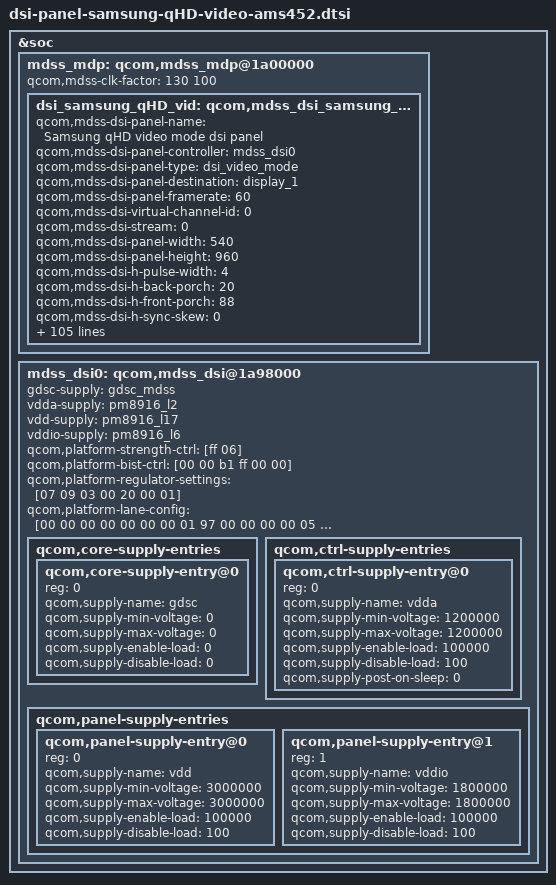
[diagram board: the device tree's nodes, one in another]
/* Copyright (c) 2013-2014, The Linux Foundation. All rights reserved.
 *
 * This program is free software; you can redistribute it and/or modify
 * it under the terms of the GNU General Public License version 2 and
 * only version 2 as published by the Free Software Foundation.
 *
 * This program is distributed in the hope that it will be useful,
 * but WITHOUT ANY WARRANTY; without even the implied warranty of
 * MERCHANTABILITY or FITNESS FOR A PARTICULAR PURPOSE.  See the
 * GNU General Public License for more details.
 */

/*---------------------------------------------------------------------------
 * This file is autogenerated file using gcdb parser. Please do not edit it.
 * Update input XML file to add a new entry or update variable in this file
 * VERSION = "1.0"
 *---------------------------------------------------------------------------

 */
&mdss_mdp {
	dsi_samsung_qHD_vid: qcom,mdss_dsi_samsung_qHD_video {
		qcom,mdss-dsi-panel-name = "Samsung qHD video mode dsi panel";
		qcom,mdss-dsi-panel-controller = <&mdss_dsi0>;
		qcom,mdss-dsi-panel-type = "dsi_video_mode";
		qcom,mdss-dsi-panel-destination = "display_1";
		qcom,mdss-dsi-panel-framerate = <60>;
		qcom,mdss-dsi-virtual-channel-id = <0>;
		qcom,mdss-dsi-stream = <0>;
		qcom,mdss-dsi-panel-width = <540>;
		qcom,mdss-dsi-panel-height = <960>;
		qcom,mdss-dsi-h-pulse-width = <4>;
		qcom,mdss-dsi-h-back-porch = <20>;
		qcom,mdss-dsi-h-front-porch = <88>;
		qcom,mdss-dsi-h-sync-skew = <0>;
		qcom,mdss-dsi-v-pulse-width = <2>;
		qcom,mdss-dsi-v-back-porch = <8>;
		qcom,mdss-dsi-v-front-porch = <14>;
		qcom,mdss-dsi-panel-timings = [88 1C 12 00 42 44 18 20 16 03 04 00];
		qcom,mdss-dsi-t-clk-post = <0x04>;
		qcom,mdss-dsi-t-clk-pre = <0x27>;
		qcom,mdss-dsi-h-left-border = <0>;
		qcom,mdss-dsi-h-right-border = <0>;
		qcom,mdss-dsi-v-top-border = <0>;
		qcom,mdss-dsi-v-bottom-border = <0>;
		qcom,mdss-dsi-bpp = <24>;
		qcom,mdss-dsi-underflow-color = <0xff>;
		qcom,mdss-dsi-border-color = <0>;
		qcom,esd-irq-gpio = <&msm_gpio 56 0>;
		qcom,mdss-dsi-on-command = [
			39 01 00 00 00 00 03 f0 5a 5a /* Tesk key ON */
			39 01 00 00 00 00 03 fc 5a 5a /* Tesk key ON */
			39 01 00 00 00 00 02 cc 4c
			05 01 00 00 78 00 02 11 00 /* Sleep out  wait 120ms */

			/* Brightness condition set */
			39 01 00 00 00 00 22 /* Brightness gamma */
				ca 01 00 01 00 01 00 80
				80 80 80 80 80 80 80 80
				80 80 80 80 80 80 80 80
				80 80 80 80 80 80 80 00
				00 00

			39 01 00 00 00 00 06 b2 40 0A 17 00 0A /* AID set */
			39 01 00 00 00 00 03 b6 28 0B /* ELVSS */

			/* ETC */
			39 01 00 00 00 00 02 55 00 /* ACL set */
			39 01 00 00 00 00 03 fc a5 a5
			05 01 00 00 00 00 02 29 00 /* Display on */];
		qcom,mdss-dsi-on-command-revC = [
			39 01 00 00 00 00 03 f0 5a 5a /* Tesk key ON */
			39 01 00 00 00 00 03 fc 5a 5a /* Tesk key ON */
			39 01 00 00 00 00 02 cc 4c
			05 01 00 00 78 00 02 11 00 /* Sleep out  wait 120ms */

			/* Brightness condition set */
			39 01 00 00 00 00 22 /* Brightness gamma */
				ca 01 00 01 00 01 00 80
				80 80 80 80 80 80 80 80
				80 80 80 80 80 80 80 80
				80 80 80 80 80 80 80 00
				00 00

			39 01 00 00 00 00 06 b2 40 0A 17 00 0A /* AID set */
			39 01 00 00 00 00 03 b6 2c 1B /* ELVSS */

			/* ETC */
			39 01 00 00 00 00 02 55 00 /* ACL set */
			39 01 00 00 00 00 03 fc a5 a5
			05 01 00 00 00 00 02 29 00 /* Display on */];

		qcom,mdss-dsi-off-command = [05 01 00 00 23 00 02 28 00
				 05 01 00 00 78 00 02 10 00];
		qcom,mdss-dsi-gamma-update = [39 01 00 00 00 00 02 F7 03];
		qcom,mdss-dsi-on-command-state = "dsi_lp_mode";
		qcom,mdss-dsi-off-command-state = "dsi_hs_mode";
		qcom,mdss-dsi-h-sync-pulse = <0>;
		qcom,mdss-dsi-traffic-mode = "burst_mode";
		qcom,mdss-dsi-bllp-eof-power-mode;
		qcom,mdss-dsi-bllp-power-mode;
		qcom,mdss-dsi-lane-0-state;
		qcom,mdss-dsi-lane-1-state;
		qcom,mdss-dsi-bl-min-level = <1>;
		qcom,mdss-dsi-bl-max-level = <255>;
		qcom,mdss-dsi-dma-trigger = "trigger_sw";
		qcom,mdss-dsi-mdp-trigger = "none";
		qcom,mdss-force-clk-lane-hs = <1>;
		qcom,mdss-dsi-bl-pmic-control-type = "bl_ctrl_dcs";
		qcom,mdss-dsi-reset-sequence = <1 5>, <0 1>, <1 10>;
		qcom,mdss-pan-physical-width-dimension = <56>;
		qcom,mdss-pan-physical-height-dimension = <100>;
		qcom,mdss-dsi-lp11-init;
		qcom,mdss-dsi-init-delay-us = <2000>;
		samsung,panel-manufacture-id-read-cmds = [
			06 01 00 00 00 00 01 DA 01 00
			06 01 00 00 00 00 01 DB 01 00
			06 01 00 00 00 00 01 DC 01 00
		];
		samsung,panel-acl-off-cmds = [39 01 00 00 72 00 02 55 00];
		/*
		the last byte in read commands  represent READ LENGH,
		like below  READ LENGH = 0x21
		*/

		samsung,panel-mtp-read-cmds = [ 39 01 00 00 00 00 03 FD DA 00 ];
		samsung,panel-ddi-id-read-cmds = [06 01 00 00 00 00 01 D5 05 00 ];
		samsung,panel-nv-mtp-read-cmds = [ 06 01 00 00 00 00 01 C8 21 00];
		samsung,panel-nv-mtp-read-hbm-cmds = [ 06 01 00 00 00 00 01 B5 07 0C];	/* read B5 13~19th , 12=0x0C*/
		samsung,panel-nv-mtp-read-hbm2-cmds = [ 06 01 00 00 00 00 01 B5 03 19];	/* read B5 26~28th , 25=0x19*/
		samsung,panel-nv-mtp-read-hbm3-cmds = [ 06 01 00 00 00 00 01 B6 11 00];	/* read B6 03~17th , 03=0x03*/
		samsung,panel-nv-mtp-read-hbm3-cmds-revC = [ 06 01 00 00 00 00 01 B6 0D 10];	/* read B6 03~17th , 03=0x03*/
		samsung,panel-test-key-enable-cmds = [ 39 00 00 00 00 00 03 F0 5A 5A];
		samsung,panel-test-key-disable-cmds = [ 39 01 00 00 00 00 03 F0 A5 A5];
		samsung,panel-nv-mdnie-read-cmds = [ 06 01 00 00 00 00 01 B5 04 13];
		samsung,panel-nv-mdate-read-cmds = [ 06 01 00 00 00 00 01 B5 02 17];	/* read B6 24~25th , 23=0x17*/

		samsung,panel-nv-read-enable-cmds = [39 01 00 00 00 00 03 F0 5A 5A
						39 01 00 00 00 00 03 FC 5A 5A];
		samsung,panel-nv-read-disable-cmds = [39 01 00 00 00 00 03 FC A5 A5
						39 01 00 00 00 00 03 F0 A5 A5];

		samsung,panel-gamma-hbm-cmds-list = [39 00 00 00 00 00 22            /* Brightness Condition Set - Gamma 2.2 Setting*/
						ca 01 00 01 00 01 00 80
						80 80 80 80 80 80 80 80
						80 80 80 80 80 80 80 80
						80 80 80 80 80 80 80 00
						00 00
			];

		samsung,panel-etc-hbm-cmds = [
					39 00 00 00 00 00 06 B2 40 0A 17 00 0A	/* samsung_brightness_aor_condition */
					39 00 00 00 00 00 03 B6 28 0B	/* C8h 40th - MPS / ELVSS setting */
					39 00 00 00 00 00 02 B0 10
					39 00 00 00 00 00 02 B6 00
					39 00 00 00 00 00 02 55 01		/* power saving Set */
					39 00 00 00 00 00 02 F7 03		/* Gamma, LTPS(AID) update */
		];
		samsung,panel-etc-hbm-cmds-revC = [
					39 00 00 00 00 00 06 B2 40 0A 17 00 0A	/* samsung_brightness_aor_condition */
					39 00 00 00 00 00 03 B6 2c 0B	/* C8h 40th - MPS / ELVSS setting */
					39 00 00 00 00 00 02 B0 10
					39 00 00 00 00 00 02 B6 00
					39 00 00 00 00 00 02 55 01		/* power saving Set */
					39 00 00 00 00 00 02 F7 03		/* Gamma, LTPS(AID) update */
		];

		samsung,panel-hbm-off-cmds = [
					39 00 00 00 00 00 03 B6 28 0B	/* C8h 40th - MPS / ELVSS setting */
					39 00 00 00 00 00 02 B0 10
					39 00 00 00 00 00 02 B6 00
					39 01 00 00 00 00 02 F7 03		/* Gamma, LTPS(AID) update */
		];
		samsung,panel-hbm-off-cmds-revC = [
					39 00 00 00 00 00 03 B6 2c 0B	/* C8h 40th - MPS / ELVSS setting */
					39 00 00 00 00 00 02 B0 10
					39 00 00 00 00 00 02 B6 00
					39 01 00 00 00 00 02 F7 03		/* Gamma, LTPS(AID) update */
		];
		samsung,panel-elvss-temp-cmds = [
					39 00 00 00 00 00 03 F0 5A 5A
					39 00 00 00 00 00 02 B0 05
					39 00 00 00 00 00 03 B8 1e 13
		];
		/*
		* ************************************************************************************************************************
		* AID command list and mappings
		* ************************************************************************************************************************
		*/
		samsung,panel-aid-cmds-list-350 = [
			39 00 00 00 00 00 06 B2 40 0A 17 03 AC /* 0 samsung_brightness_aor_0p4 */
			39 00 00 00 00 00 06 B2 40 0A 17 03 A5 /* 1 samsung_brightness_aor_40p0 */
			39 00 00 00 00 00 06 B2 40 0A 17 03 9B /* 2 samsung_brightness_aor_0p4 181*/
			39 00 00 00 00 00 06 B2 40 0A 17 03 93 /* 3 samsung_brightness_aor_0p4 179*/
			39 00 00 00 00 00 06 B2 40 0A 17 03 89 /* 4 samsung_brightness_aor_0p4 177*/
			39 00 00 00 00 00 06 B2 40 0A 17 03 80 /* 5 samsung_brightness_aor_0p4 175*/
			39 00 00 00 00 00 06 B2 40 0A 17 03 77 /* 6 samsung_brightness_aor_0p4 173*/
			39 00 00 00 00 00 06 B2 40 0A 17 03 6F /* 7 samsung_brightness_aor_0p4 110*/
			39 00 00 00 00 00 06 B2 40 0A 17 03 65 /* 8 samsung_brightness_aor_0p4 109*/
			39 00 00 00 00 00 06 B2 40 0A 17 03 5C /* 9 samsung_brightness_aor_0p4 108*/
			39 00 00 00 00 00 06 B2 40 0A 17 03 52 /* 10 samsung_brightness_aor_0p4 */
			39 00 00 00 00 00 06 B2 40 0A 17 03 4A /* 11 samsung_brightness_aor_0p4 108*/
			39 00 00 00 00 00 06 B2 40 0A 17 03 41 /* 12 samsung_brightness_aor_0p4 */
			39 00 00 00 00 00 06 B2 40 0A 17 03 2F /* 13 samsung_brightness_aor_0p4 */
			39 00 00 00 00 00 06 B2 40 0A 17 03 25 /* 14 samsung_brightness_aor_6p2 */
			39 00 00 00 00 00 06 B2 40 0A 17 03 1D /* 15 samsung_brightness_aor_81p6 */
			39 00 00 00 00 00 06 B2 40 0A 17 03 12 /* 16 samsung_brightness_aor_80p6 */
			39 00 00 00 00 00 06 B2 40 0A 17 03 01 /* 17 samsung_brightness_aor_79p0 */
			39 00 00 00 00 00 06 B2 40 0A 17 02 F7 /* 18 samsung_brightness_aor_77p9 */
			39 00 00 00 00 00 06 B2 40 0A 17 02 E5 /* 19 samsung_brightness_aor_75p8 */
			39 00 00 00 00 00 06 B2 40 0A 17 02 D3 /* 20samsung_brightness_aor_74p3 */
			39 00 00 00 00 00 06 B2 40 0A 17 02 C8 /* 21 samsung_brightness_aor_73p2 */
			39 00 00 00 00 00 06 B2 40 0A 17 02 B7 /* 22 samsung_brightness_aor_71p7 */
			39 00 00 00 00 00 06 B2 40 0A 17 02 A2 /* 23 samsung_brightness_aor_69p5 */
			39 00 00 00 00 00 06 B2 40 0A 17 02 87 /* 24 samsung_brightness_aor_66p9 */
			39 00 00 00 00 00 06 B2 40 0A 17 02 74 /* 25 samsung_brightness_aor_64p7 */
			39 00 00 00 00 00 06 B2 40 0A 17 02 5F /* 26 samsung_brightness_aor_63p1 */
			39 00 00 00 00 00 06 B2 40 0A 17 02 42 /* 27 samsung_brightness_aor_59p9 */
			39 00 00 00 00 00 06 B2 40 0A 17 02 22 /* 28 samsung_brightness_aor_57p3 */
			39 00 00 00 00 00 06 B2 40 0A 17 02 05 /* 29 samsung_brightness_aor_54p6 */
			39 00 00 00 00 00 06 B2 40 0A 17 01 E5 /* 30 samsung_brightness_aor_51p9 */
			39 00 00 00 00 00 06 B2 40 0A 17 01 C7 /* 31 samsung_brightness_aor_48p6 */
			39 00 00 00 00 00 06 B2 40 0A 17 01 9E /* 32 samsung_brightness_aor_48p6 */
			39 00 00 00 00 00 06 B2 40 0A 17 01 78 /* 33 samsung_brightness_aor_48p6 */
			39 00 00 00 00 00 06 B2 40 0A 17 01 4F /* 34 samsung_brightness_aor_44p8 */
			39 00 00 00 00 00 06 B2 40 0A 17 01 22 /* 35 samsung_brightness_aor_41p0 */
			39 00 00 00 00 00 06 B2 40 0A 17 00 EF /* 36 samsung_brightness_aor_37p2 */
			39 00 00 00 00 00 06 B2 40 0A 17 00 BD /* 37 samsung_brightness_aor_32p7 */
			39 00 00 00 00 00 06 B2 40 0A 17 00 85 /* 38 samsung_brightness_aor_27p7 */
			39 00 00 00 00 00 06 B2 40 0A 17 00 49 /* 39 samsung_brightness_aor_22p8 */
			39 00 00 00 00 00 06 B2 40 0A 17 00 0A /* 40 samsung_brightness_aor_0p5 */
		];

		samsung,panel-aid-map-table-350 = <
			5	0		6	1		7	2		8	3		9	4
			10	5		11	6		12	7		13	8		14	9
			15	10		16	11		17	12		19	13		20	14
			21	15		22	16		24	17		25	18		27	19
			29	20		30	21		32	22		34	23		37	24
			39	25		41	26		44	27		47	28		50	29
			53	30		56	31		60	32		64	33		68	33
			72	33		77	33		82	33		87	33		93	33
			98	33		105	33		111	33		119	33		126	33
			134	33		143	33		152	33		162	33		172	34
			183	35		195	36		207	37		220	38		234	39
			249	40		265	40		282	40		300	40		316	40
			333	40		350	40
		>;
		/*
		* ************************************************************************************************************************
		* ACL command list and mappings
		* ************************************************************************************************************************
		*/
		samsung,panel-acl-cmds-list = [
			39 00 00 00 00 00 02 55 00
			39 00 00 00 00 00 02 55 01
			39 00 00 00 00 00 02 55 02
			39 00 00 00 00 00 02 55 03
		];

		samsung,panel-acl-map-table =  <
			5    1         6    1        7    1         8    1      9    1
			10   1         11   1        12   1         13   1      14   1
			15   1         16   1        17   1         19   1      20   1
			21   1         22   1        24   1         25   1      27   1
			29   1         30   1        32   1         34   1      37   1
			39   1         41   1        44   1         47   1      50   1
			53   1         56   1        60   1         64   1      68   1
			72   1         77   1        82   1         87   1      93   1
			98   1         105  1        111  1         119  1      126  1
			134  1         143  1        152  1         162  1      172  1
			183  1         195  1        207  1         220  1      234  1
			249  1         265  1        282  1         300  1      316  1
			333  1         350  1
		>;
		/*
		* ************************************************************************************************************************
		* ELVSS(ACL Off) command list and mappings
		* ************************************************************************************************************************
		*/
		samsung,panel-elvss-cmds-list-350 = [
			39 00 00 00 00 00 03 B6 28 17 /* 0 DEFAULT_ELVSS(0x17) */
			39 00 00 00 00 00 03 B6 28 16 /* 1 DEFAULT_ELVSS(0x16) */
			39 00 00 00 00 00 03 B6 28 15 /* 2 DEFAULT_ELVSS(0x15) */
			39 00 00 00 00 00 03 B6 28 14 /* 3 DEFAULT_ELVSS(0x14) */
			39 00 00 00 00 00 03 B6 28 13 /* 4 DEFAULT_ELVSS(0x13) */
			39 00 00 00 00 00 03 B6 28 12 /* 5 DEFAULT_ELVSS(0x12) */
			39 00 00 00 00 00 03 B6 28 11 /* 6 DEFAULT_ELVSS(0x11) */
			39 00 00 00 00 00 03 B6 28 10 /* 7 DEFAULT_ELVSS(0x10) */
			39 00 00 00 00 00 03 B6 28 0F /* 8 DEFAULT_ELVSS(0x0F) */
			39 00 00 00 00 00 03 B6 28 0E /* 9 DEFAULT_ELVSS(0x0E) */
			39 00 00 00 00 00 03 B6 28 0D /* 10 DEFAULT_ELVSS(0x0D) */
			39 00 00 00 00 00 03 B6 28 0C /* 11 DEFAULT_ELVSS(0x0C) */
			39 00 00 00 00 00 03 B6 28 0B /* 12 DEFAULT_ELVSS(0x0B) */
		];
		/* bl_level, Index in elvss command list */
		samsung,panel-elvss-map-table-350 = <
			5    0         6    0        7    0         8    0      9    0
			10   0         11   0        12   0         13   0      14   0
			15   0         16   0        17   0         19   0      20   0
			21   0         22   0        24   0         25   0      27   0
			29   0         30   0        32   0         34   0      37   0
			39   0         41   0        44   1         47   1      50   1
			53   1         56   1        60   2         64   2      68   3
			72   3         77   3        82   3         87   4      93   4
			98   4         105  5        111  5         119  6      126  6
			134  6         143  7        152  7         162  7      172  7
			183  7        195  7       207  7        220  7     234  7
			249  7        265  7       282  8        300   9     316  10
			333  11        350  11
			>;
		samsung,panel-elvss-cmds-list-350-revC = [
			39 00 00 00 00 00 03 B6 2c 17 /* 0 DEFAULT_ELVSS(0x27) */
			39 00 00 00 00 00 03 B6 2c 16 /* 1 DEFAULT_ELVSS(0x26) */
			39 00 00 00 00 00 03 B6 2c 15 /* 2 DEFAULT_ELVSS(0x25) */
			39 00 00 00 00 00 03 B6 2c 14 /* 3 DEFAULT_ELVSS(0x24) */
			39 00 00 00 00 00 03 B6 2c 13 /* 4 DEFAULT_ELVSS(0x23) */
			39 00 00 00 00 00 03 B6 2c 12 /* 5 DEFAULT_ELVSS(0x22) */
			39 00 00 00 00 00 03 B6 2c 11 /* 6 DEFAULT_ELVSS(0x21) */
			39 00 00 00 00 00 03 B6 2c 10 /* 7 DEFAULT_ELVSS(0x20) */
			39 00 00 00 00 00 03 B6 2c 0F /* 8 DEFAULT_ELVSS(0x1F) */
			39 00 00 00 00 00 03 B6 2c 0E /* 9 DEFAULT_ELVSS(0x1E) */
			39 00 00 00 00 00 03 B6 2c 0D /* 10 DEFAULT_ELVSS(0x1D) */
			39 00 00 00 00 00 03 B6 2c 0C /* 11 DEFAULT_ELVSS(0x1C) */
			39 00 00 00 00 00 03 B6 2c 0B /* 12 DEFAULT_ELVSS(0x1B) */
		];
		/* bl_level, Index in elvss command list */
		samsung,panel-elvss-map-table-350-revC = <
			5	0		6	0		7	0		8	0		9	0
			10	0		11	0		12	0		13	0		14	0
			15	0		16	0		17	0		19	0		20	0
			21	0		22	0		24	0		25	0		27	0
			29	0		30	0		32	0		34	0		37	0
			39	0		41	0		44	0		47	0		50	0
			53	0		56	0		60	0		64	0		68	0
			72	0		77	0		82	1		87	1		93	2
			98	2		105	2		111	3		119	3		126	4
			134	4		143	5		152	5		162	6		172	6
			183	7		195	7		207	7		220	7		234	8
			249	8		265	8		282	9		300	10		316	11
			333	11		350	12
			>;

		/*
		* ************************************************************************************************************************
		* candela to index mappings
		* ************************************************************************************************************************
		*/
		samsung,panel-candella-mapping-table-350 = <
		/*<idx>	  <from>  <till> <candella> */
				0		0		5		5
				1		6		6		6
				2		7		7		7
				3		8		8		8
				4		9		9		9
				5		10		10		10
				6		11		11		11
				7		12		12		12
				8		13		13		13
				9		14		14		14
				10		15		15		15
				11		16		16		16
				12		17		17		17
				13		18		18		19
				14		19		19		20
				15		20		20		21
				16		21		21		22
				17		22		22		24
				18		23		23		25
				19		24		24		27
				20		25		25		29
				21		26		26		30
				22		27		27		32
				23		28		28		34
				24		29		29		37
				25		30		30		39
				26		31		32		41
				27		33		34		44
				28		35		36		47
				29		37		38		50
				30		39		40		53
				31		41		43		56
				32		44		46		60
				33		47		49		64
				34		50		52		68
				35		53		56		72
				36		57		59		77
				37		60		63		82
				38		64		67		87
				39		68		71		93
				40		72		76		98
				41		77		80		105
				42		81		86		111
				43		87		91		119
				44		92		97		126
				45		98		104		134
				46		105		110		143
				47		111		118		152
				48		119		125		162
				49		126		133		172
				50		134		142		183
				51		143		150		195
				52		151		160		207
				53		161		170		220
				54		171		181		234
				55		182		193		249
				56		194		205		265
				57		206		218		282
				58		219		230		300
				59		231		242		316
				60		243		254		333
				61		255		255		350
		>;
		samsung,panel-gamma-cmds-list = [
			39 00 00 00 00 00 22 CA 01		/* Brightness Condition Set - Gamma 2.2 Setting*/
			00 01 00 01 00 80 80 80
			80 80 80 80 80 80 80 80
			80 80 80 80 80 80 80 80
			80 80 80 80 80 00 00 00
			39 00 00 00 00 00 02 F7 03
		];
	};
};

&soc {
	mdss_mdp: qcom,mdss_mdp@1a00000 {
			qcom,mdss-clk-factor = <130 100>;	/* 1.3 times */
	};
};

&soc {
	mdss_dsi0: qcom,mdss_dsi@1a98000 {
		gdsc-supply = <&gdsc_mdss>;
		vdda-supply = <&pm8916_l2>;
		vdd-supply = <&pm8916_l17>;
		vddio-supply = <&pm8916_l6>;
		qcom,platform-strength-ctrl = [ff 06];
		qcom,platform-bist-ctrl = [00 00 b1 ff 00 00];
		qcom,platform-regulator-settings = [07 09 03 00 20 00 01];
		qcom,platform-lane-config = [00 00 00 00 00 00 00 01 97
			00 00 00 00 05 00 00 01 97
			00 00 00 00 0a 00 00 01 97
			00 00 00 00 0f 00 00 01 97
			00 c0 00 00 00 00 00 01 bb];
		qcom,core-supply-entries {
			#address-cells = <1>;
			#size-cells = <0>;

			qcom,core-supply-entry@0 {
				reg = <0>;
				qcom,supply-name = "gdsc";
				qcom,supply-min-voltage = <0>;
				qcom,supply-max-voltage = <0>;
				qcom,supply-enable-load = <0>;
				qcom,supply-disable-load = <0>;
			};
		};
		qcom,ctrl-supply-entries {
			#address-cells = <1>;
			#size-cells = <0>;

			qcom,ctrl-supply-entry@0 {
				reg = <0>;
				qcom,supply-name = "vdda";
				qcom,supply-min-voltage = <1200000>;
				qcom,supply-max-voltage = <1200000>;
				qcom,supply-enable-load = <100000>;
				qcom,supply-disable-load = <100>;
				qcom,supply-post-on-sleep = <0>;
			};
		};
		qcom,panel-supply-entries {
			#address-cells = <1>;
			#size-cells = <0>;

			qcom,panel-supply-entry@0 {
				reg = <0>;
				qcom,supply-name = "vdd";
				qcom,supply-min-voltage = <3000000>;
				qcom,supply-max-voltage = <3000000>;
				qcom,supply-enable-load = <100000>;
				qcom,supply-disable-load = <100>;
			};

			qcom,panel-supply-entry@1 {
				reg = <1>;
				qcom,supply-name = "vddio";
				qcom,supply-min-voltage = <1800000>;
				qcom,supply-max-voltage = <1800000>;
				qcom,supply-enable-load = <100000>;
				qcom,supply-disable-load = <100>;
			};
		};
	};
};
